# STM32H742AGI6 register map
File version: 1.0
Registers are 32-bit, access not given, reset 0x0 unless marked. A register's access mark holds for its fields unless they carry their own. Offsets are from the block's base; [hi:lo] are bit positions; {n}, {i} and the like mark numbered series; 'fields as' and 'values as' point back to an identical list.

## JPEG
Base 0x52003000
0x00 CONFR0
  [0] START
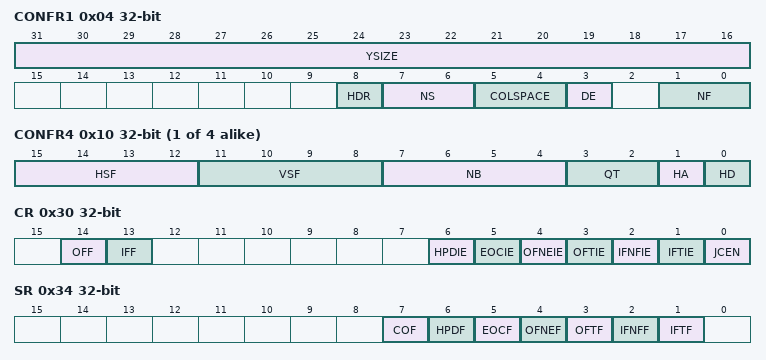
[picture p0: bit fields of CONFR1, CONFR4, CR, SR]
0x04 CONFR1
  [31:16] YSIZE, [8] HDR, [7:6] NS, [5:4] COLSPACE, [3] DE, [1:0] NF
0x08 CONFR2
  [25:0] NMCU
0x0C CONFR3
  [31:16] XSIZE
{0x0+4i} CONFR{i} (i=4..7)
  [15:12] HSF, [11:8] VSF, [7:4] NB, [3:2] QT, [1] HA, [0] HD
0x30 CR
  [14] OFF, [13] IFF, [6] HPDIE, [5] EOCIE, [4] OFNEIE, [3] OFTIE, [2] IFNFIE, [1] IFTIE, [0] JCEN
0x34 SR
  [7] COF, [6] HPDF, [5] EOCF, [4] OFNEF, [3] OFTF, [2] IFNFF, [1] IFTF
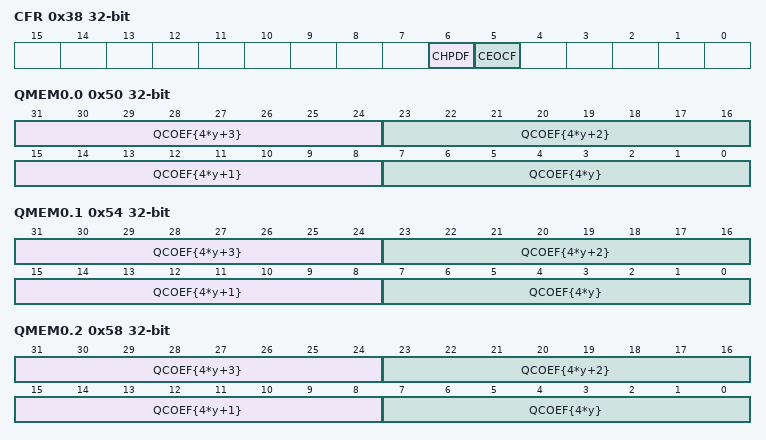
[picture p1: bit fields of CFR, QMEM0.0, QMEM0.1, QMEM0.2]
0x38 CFR
  [6] CHPDF, [5] CEOCF
0x40 DIR
  [31:0] DATAIN
0x44 DOR
  [31:0] DATAOUT
0x50 QMEM0.0
  [31:24] QCOEF{4*y+3}, [23:16] QCOEF{4*y+2}, [15:8] QCOEF{4*y+1}, [7:0] QCOEF{4*y}
0x54 QMEM0.1
  fields as QMEM0.0
0x58 QMEM0.2
  fields as QMEM0.0
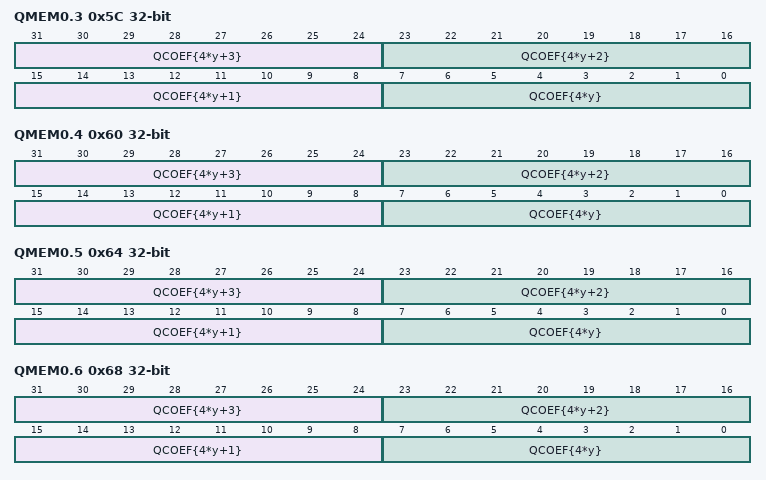
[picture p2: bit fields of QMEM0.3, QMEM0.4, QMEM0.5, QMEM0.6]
0x5C QMEM0.3
  fields as QMEM0.0
0x60 QMEM0.4
  fields as QMEM0.0
0x64 QMEM0.5
  fields as QMEM0.0
0x68 QMEM0.6
  fields as QMEM0.0
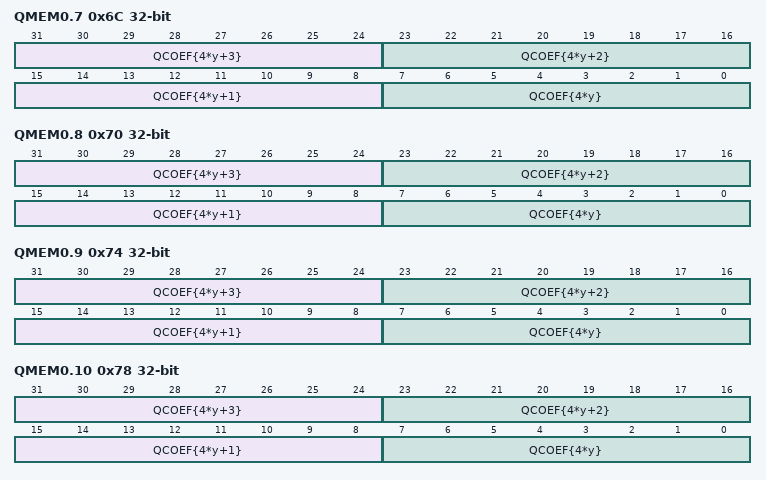
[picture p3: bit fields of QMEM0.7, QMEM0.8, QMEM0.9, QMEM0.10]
0x6C QMEM0.7
  fields as QMEM0.0
0x70 QMEM0.8
  fields as QMEM0.0
0x74 QMEM0.9
  fields as QMEM0.0
0x78 QMEM0.10
  fields as QMEM0.0
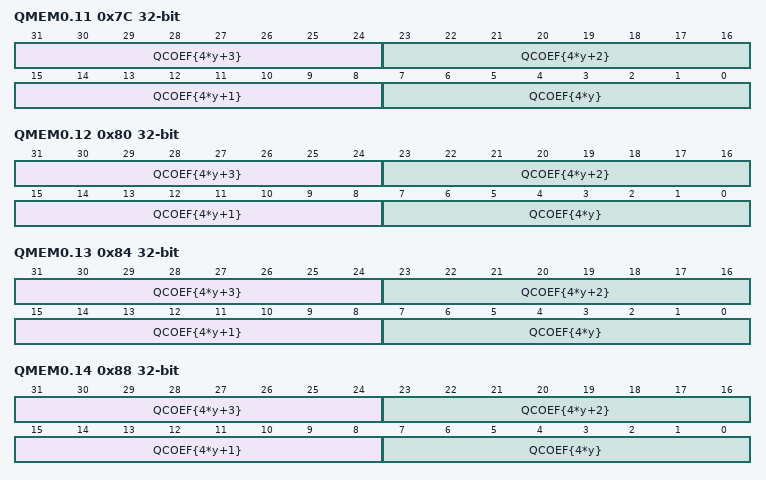
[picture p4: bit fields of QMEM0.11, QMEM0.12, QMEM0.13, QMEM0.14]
0x7C QMEM0.11
  fields as QMEM0.0
0x80 QMEM0.12
  fields as QMEM0.0
0x84 QMEM0.13
  fields as QMEM0.0
0x88 QMEM0.14
  fields as QMEM0.0
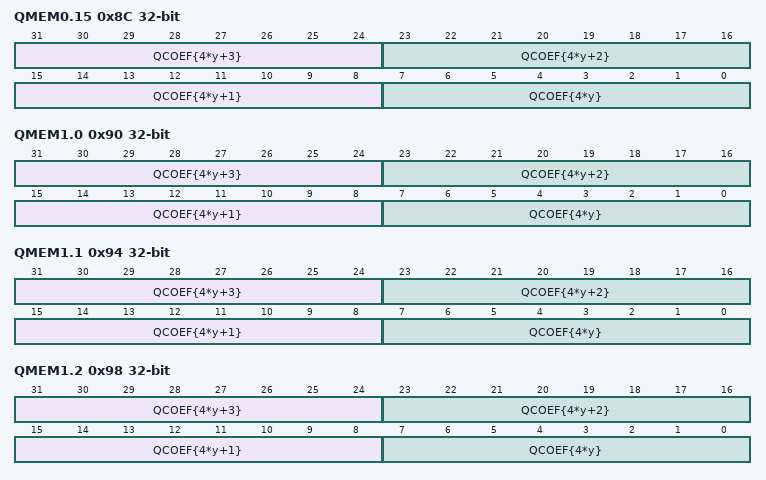
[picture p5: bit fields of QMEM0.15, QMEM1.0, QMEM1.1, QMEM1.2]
0x8C QMEM0.15
  fields as QMEM0.0
0x90 QMEM1.0
  fields as QMEM0.0
0x94 QMEM1.1
  fields as QMEM0.0
0x98 QMEM1.2
  fields as QMEM0.0
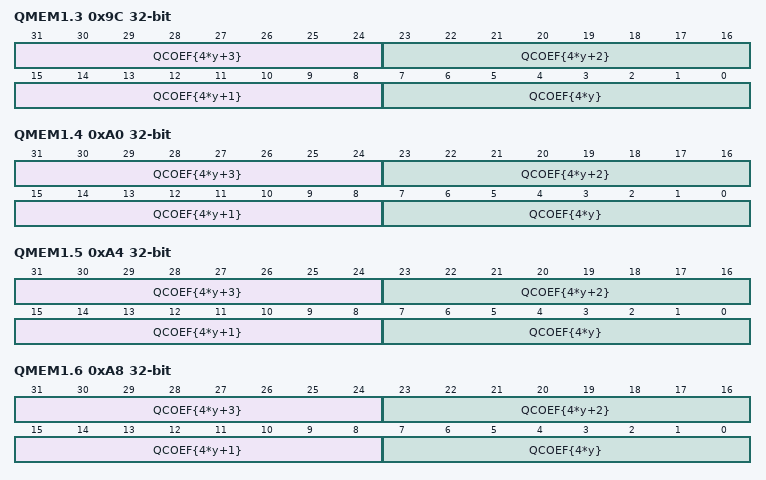
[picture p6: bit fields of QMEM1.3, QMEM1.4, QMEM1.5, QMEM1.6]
0x9C QMEM1.3
  fields as QMEM0.0
0xA0 QMEM1.4
  fields as QMEM0.0
0xA4 QMEM1.5
  fields as QMEM0.0
0xA8 QMEM1.6
  fields as QMEM0.0
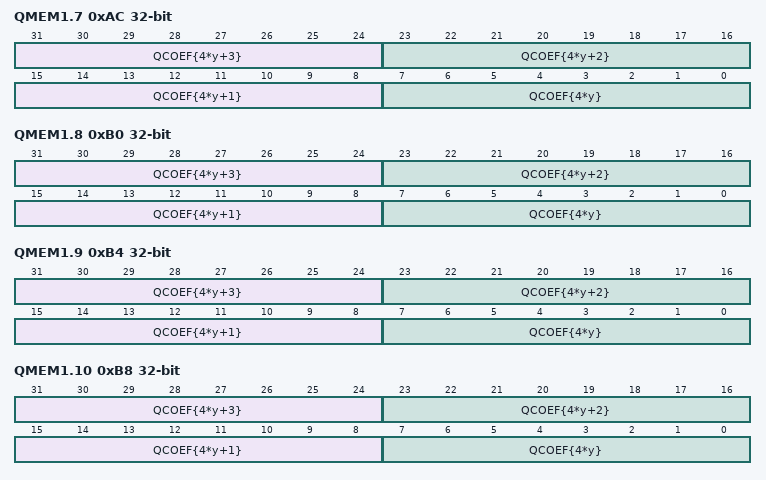
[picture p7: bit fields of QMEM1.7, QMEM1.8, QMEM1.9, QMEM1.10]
0xAC QMEM1.7
  fields as QMEM0.0
0xB0 QMEM1.8
  fields as QMEM0.0
0xB4 QMEM1.9
  fields as QMEM0.0
0xB8 QMEM1.10
  fields as QMEM0.0
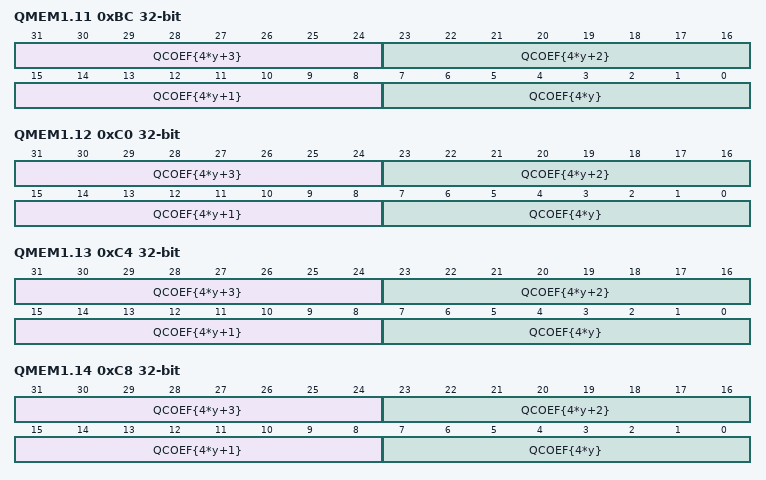
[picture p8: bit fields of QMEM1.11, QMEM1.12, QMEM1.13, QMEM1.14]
0xBC QMEM1.11
  fields as QMEM0.0
0xC0 QMEM1.12
  fields as QMEM0.0
0xC4 QMEM1.13
  fields as QMEM0.0
0xC8 QMEM1.14
  fields as QMEM0.0
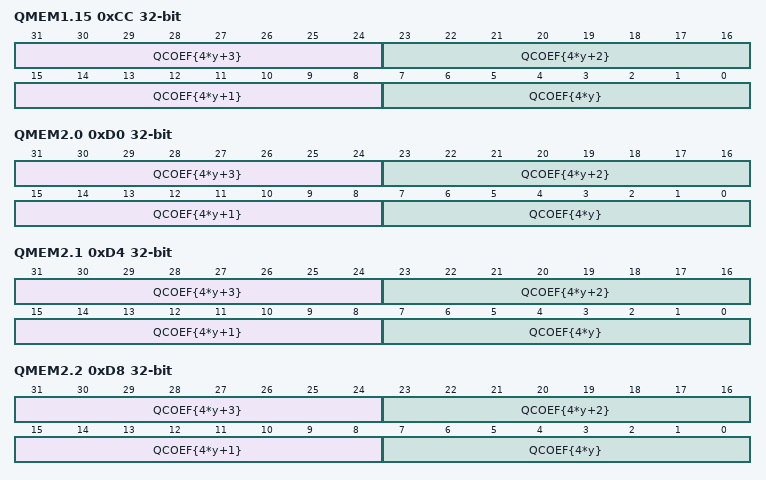
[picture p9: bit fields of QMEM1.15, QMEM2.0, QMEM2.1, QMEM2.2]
0xCC QMEM1.15
  fields as QMEM0.0
0xD0 QMEM2.0
  fields as QMEM0.0
0xD4 QMEM2.1
  fields as QMEM0.0
0xD8 QMEM2.2
  fields as QMEM0.0
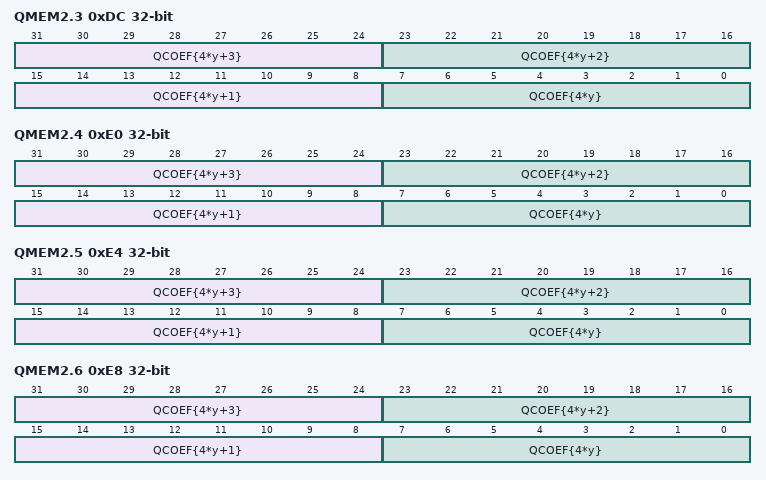
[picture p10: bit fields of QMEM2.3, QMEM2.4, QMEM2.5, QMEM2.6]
0xDC QMEM2.3
  fields as QMEM0.0
0xE0 QMEM2.4
  fields as QMEM0.0
0xE4 QMEM2.5
  fields as QMEM0.0
0xE8 QMEM2.6
  fields as QMEM0.0
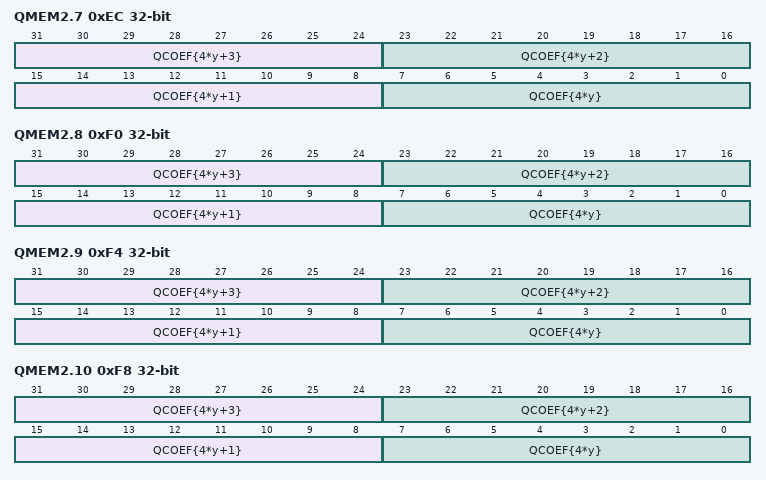
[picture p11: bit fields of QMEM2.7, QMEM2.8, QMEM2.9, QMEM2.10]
0xEC QMEM2.7
  fields as QMEM0.0
0xF0 QMEM2.8
  fields as QMEM0.0
0xF4 QMEM2.9
  fields as QMEM0.0
0xF8 QMEM2.10
  fields as QMEM0.0
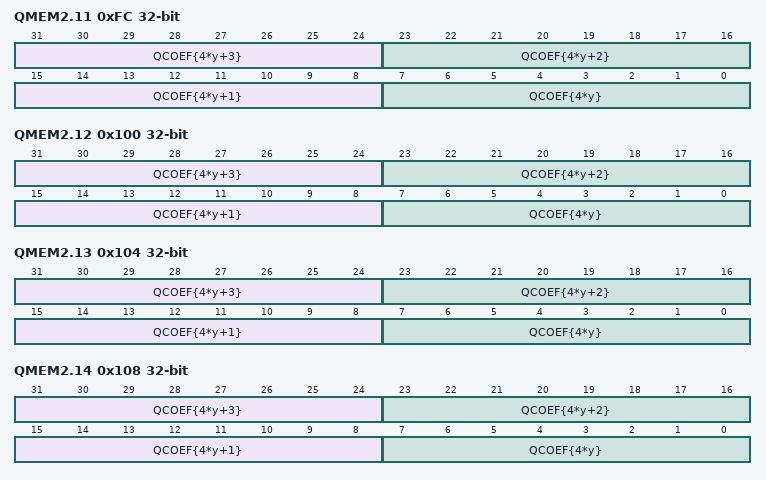
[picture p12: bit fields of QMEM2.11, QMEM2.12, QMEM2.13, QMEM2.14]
0xFC QMEM2.11
  fields as QMEM0.0
0x100 QMEM2.12
  fields as QMEM0.0
0x104 QMEM2.13
  fields as QMEM0.0
0x108 QMEM2.14
  fields as QMEM0.0
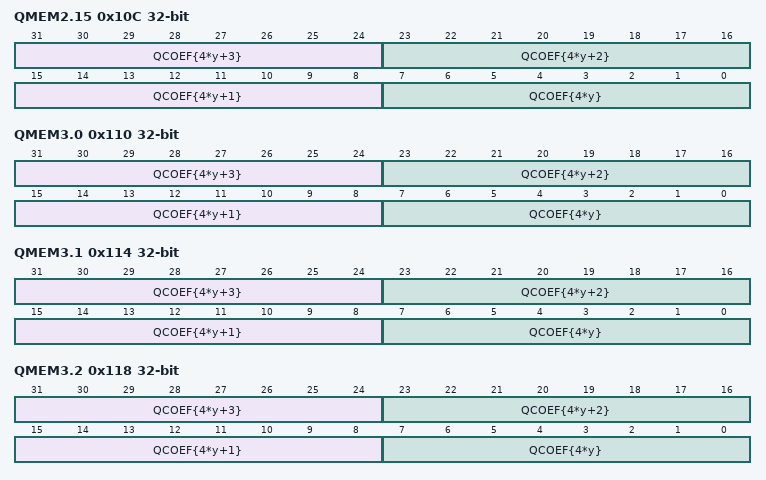
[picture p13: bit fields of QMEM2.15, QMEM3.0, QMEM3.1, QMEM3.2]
0x10C QMEM2.15
  fields as QMEM0.0
0x110 QMEM3.0
  fields as QMEM0.0
0x114 QMEM3.1
  fields as QMEM0.0
0x118 QMEM3.2
  fields as QMEM0.0
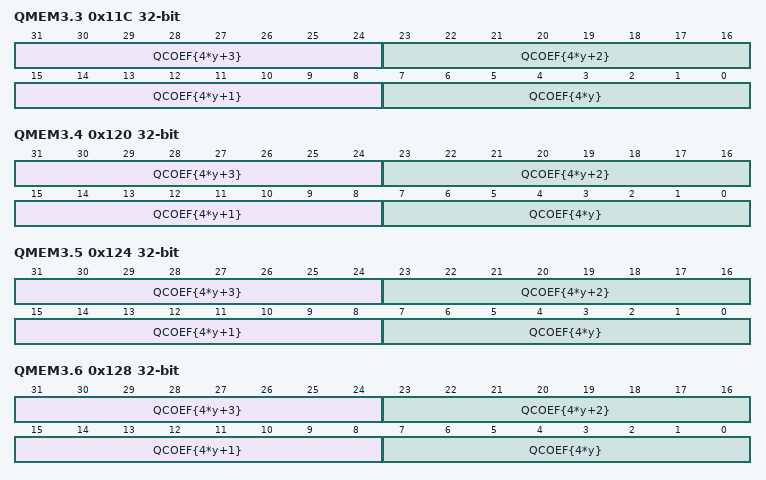
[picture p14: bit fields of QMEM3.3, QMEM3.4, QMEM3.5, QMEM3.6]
0x11C QMEM3.3
  fields as QMEM0.0
0x120 QMEM3.4
  fields as QMEM0.0
0x124 QMEM3.5
  fields as QMEM0.0
0x128 QMEM3.6
  fields as QMEM0.0
0x12C QMEM3.7
  fields as QMEM0.0
0x130 QMEM3.8
  fields as QMEM0.0
0x134 QMEM3.9
  fields as QMEM0.0
0x138 QMEM3.10
  fields as QMEM0.0
0x13C QMEM3.11
  fields as QMEM0.0
0x140 QMEM3.12
  fields as QMEM0.0
0x144 QMEM3.13
  fields as QMEM0.0
0x148 QMEM3.14
  fields as QMEM0.0
0x14C QMEM3.15
  fields as QMEM0.0
0x150 HUFFMIN.0
  [31:0] DATA{x}
0x154 HUFFMIN.1
  [31:0] DATA{x}
0x158 HUFFMIN.2
  [31:0] DATA{x}
0x15C HUFFMIN.3
  [31:0] DATA{x}
0x160 HUFFMIN.4
  [31:0] DATA{x}
0x164 HUFFMIN.5
  [31:0] DATA{x}
0x168 HUFFMIN.6
  [31:0] DATA{x}
0x16C HUFFMIN.7
  [31:0] DATA{x}
0x170 HUFFMIN.8
  [31:0] DATA{x}
0x174 HUFFMIN.9
  [31:0] DATA{x}
0x178 HUFFMIN.10
  [31:0] DATA{x}
0x17C HUFFMIN.11
  [31:0] DATA{x}
0x180 HUFFMIN.12
  [31:0] DATA{x}
0x184 HUFFMIN.13
  [31:0] DATA{x}
0x188 HUFFMIN.14
  [31:0] DATA{x}
0x18C HUFFMIN.15
  [31:0] DATA{x}
0x190 HUFFBASE.0
  [24:16] DATA{2*x+1}, [8:0] DATA{2*x}
0x194 HUFFBASE.1
  [24:16] DATA{2*x+1}, [8:0] DATA{2*x}
0x198 HUFFBASE.2
  [24:16] DATA{2*x+1}, [8:0] DATA{2*x}
0x19C HUFFBASE.3
  [24:16] DATA{2*x+1}, [8:0] DATA{2*x}
0x1A0 HUFFBASE.4
  [24:16] DATA{2*x+1}, [8:0] DATA{2*x}
0x1A4 HUFFBASE.5
  [24:16] DATA{2*x+1}, [8:0] DATA{2*x}
0x1A8 HUFFBASE.6
  [24:16] DATA{2*x+1}, [8:0] DATA{2*x}
0x1AC HUFFBASE.7
  [24:16] DATA{2*x+1}, [8:0] DATA{2*x}
0x1B0 HUFFBASE.8
  [24:16] DATA{2*x+1}, [8:0] DATA{2*x}
0x1B4 HUFFBASE.9
  [24:16] DATA{2*x+1}, [8:0] DATA{2*x}
0x1B8 HUFFBASE.10
  [24:16] DATA{2*x+1}, [8:0] DATA{2*x}
0x1BC HUFFBASE.11
  [24:16] DATA{2*x+1}, [8:0] DATA{2*x}
0x1C0 HUFFBASE.12
  [24:16] DATA{2*x+1}, [8:0] DATA{2*x}
0x1C4 HUFFBASE.13
  [24:16] DATA{2*x+1}, [8:0] DATA{2*x}
0x1C8 HUFFBASE.14
  [24:16] DATA{2*x+1}, [8:0] DATA{2*x}
0x1CC HUFFBASE.15
  [24:16] DATA{2*x+1}, [8:0] DATA{2*x}
0x1D0 HUFFBASE.16
  [24:16] DATA{2*x+1}, [8:0] DATA{2*x}
0x1D4 HUFFBASE.17
  [24:16] DATA{2*x+1}, [8:0] DATA{2*x}
0x1D8 HUFFBASE.18
  [24:16] DATA{2*x+1}, [8:0] DATA{2*x}
0x1DC HUFFBASE.19
  [24:16] DATA{2*x+1}, [8:0] DATA{2*x}
0x1E0 HUFFBASE.20
  [24:16] DATA{2*x+1}, [8:0] DATA{2*x}
0x1E4 HUFFBASE.21
  [24:16] DATA{2*x+1}, [8:0] DATA{2*x}
0x1E8 HUFFBASE.22
  [24:16] DATA{2*x+1}, [8:0] DATA{2*x}
0x1EC HUFFBASE.23
  [24:16] DATA{2*x+1}, [8:0] DATA{2*x}
0x1F0 HUFFBASE.24
  [24:16] DATA{2*x+1}, [8:0] DATA{2*x}
0x1F4 HUFFBASE.25
  [24:16] DATA{2*x+1}, [8:0] DATA{2*x}
0x1F8 HUFFBASE.26
  [24:16] DATA{2*x+1}, [8:0] DATA{2*x}
0x1FC HUFFBASE.27
  [24:16] DATA{2*x+1}, [8:0] DATA{2*x}
0x200 HUFFBASE.28
  [24:16] DATA{2*x+1}, [8:0] DATA{2*x}
0x204 HUFFBASE.29
  [24:16] DATA{2*x+1}, [8:0] DATA{2*x}
0x208 HUFFBASE.30
  [24:16] DATA{2*x+1}, [8:0] DATA{2*x}
0x20C HUFFBASE.31
  [24:16] DATA{2*x+1}, [8:0] DATA{2*x}
0x210 HUFFSYMB.0
  [31:24] DATA{4*x+3}, [23:16] DATA{4*x+2}, [15:8] DATA{4*x+1}, [7:0] DATA{4*x}
0x214 HUFFSYMB.1
  fields as HUFFSYMB.0
0x218 HUFFSYMB.2
  fields as HUFFSYMB.0
0x21C HUFFSYMB.3
  fields as HUFFSYMB.0
0x220 HUFFSYMB.4
  fields as HUFFSYMB.0
0x224 HUFFSYMB.5
  fields as HUFFSYMB.0
0x228 HUFFSYMB.6
  fields as HUFFSYMB.0
0x22C HUFFSYMB.7
  fields as HUFFSYMB.0
0x230 HUFFSYMB.8
  fields as HUFFSYMB.0
0x234 HUFFSYMB.9
  fields as HUFFSYMB.0
0x238 HUFFSYMB.10
  fields as HUFFSYMB.0
0x23C HUFFSYMB.11
  fields as HUFFSYMB.0
0x240 HUFFSYMB.12
  fields as HUFFSYMB.0
0x244 HUFFSYMB.13
  fields as HUFFSYMB.0
0x248 HUFFSYMB.14
  fields as HUFFSYMB.0
0x24C HUFFSYMB.15
  fields as HUFFSYMB.0
0x250 HUFFSYMB.16
  fields as HUFFSYMB.0
0x254 HUFFSYMB.17
  fields as HUFFSYMB.0
0x258 HUFFSYMB.18
  fields as HUFFSYMB.0
0x25C HUFFSYMB.19
  fields as HUFFSYMB.0
0x260 HUFFSYMB.20
  fields as HUFFSYMB.0
0x264 HUFFSYMB.21
  fields as HUFFSYMB.0
0x268 HUFFSYMB.22
  fields as HUFFSYMB.0
0x26C HUFFSYMB.23
  fields as HUFFSYMB.0
0x270 HUFFSYMB.24
  fields as HUFFSYMB.0
0x274 HUFFSYMB.25
  fields as HUFFSYMB.0
0x278 HUFFSYMB.26
  fields as HUFFSYMB.0
0x27C HUFFSYMB.27
  fields as HUFFSYMB.0
0x280 HUFFSYMB.28
  fields as HUFFSYMB.0
0x284 HUFFSYMB.29
  fields as HUFFSYMB.0
0x288 HUFFSYMB.30
  fields as HUFFSYMB.0
0x28C HUFFSYMB.31
  fields as HUFFSYMB.0
0x290 HUFFSYMB.32
  fields as HUFFSYMB.0
0x294 HUFFSYMB.33
  fields as HUFFSYMB.0
0x298 HUFFSYMB.34
  fields as HUFFSYMB.0
0x29C HUFFSYMB.35
  fields as HUFFSYMB.0
0x2A0 HUFFSYMB.36
  fields as HUFFSYMB.0
0x2A4 HUFFSYMB.37
  fields as HUFFSYMB.0
0x2A8 HUFFSYMB.38
  fields as HUFFSYMB.0
0x2AC HUFFSYMB.39
  fields as HUFFSYMB.0
0x2B0 HUFFSYMB.40
  fields as HUFFSYMB.0
0x2B4 HUFFSYMB.41
  fields as HUFFSYMB.0
0x2B8 HUFFSYMB.42
  fields as HUFFSYMB.0
0x2BC HUFFSYMB.43
  fields as HUFFSYMB.0
0x2C0 HUFFSYMB.44
  fields as HUFFSYMB.0
0x2C4 HUFFSYMB.45
  fields as HUFFSYMB.0
0x2C8 HUFFSYMB.46
  fields as HUFFSYMB.0
0x2CC HUFFSYMB.47
  fields as HUFFSYMB.0
0x2D0 HUFFSYMB.48
  fields as HUFFSYMB.0
0x2D4 HUFFSYMB.49
  fields as HUFFSYMB.0
0x2D8 HUFFSYMB.50
  fields as HUFFSYMB.0
0x2DC HUFFSYMB.51
  fields as HUFFSYMB.0
0x2E0 HUFFSYMB.52
  fields as HUFFSYMB.0
0x2E4 HUFFSYMB.53
  fields as HUFFSYMB.0
0x2E8 HUFFSYMB.54
  fields as HUFFSYMB.0
0x2EC HUFFSYMB.55
  fields as HUFFSYMB.0
0x2F0 HUFFSYMB.56
  fields as HUFFSYMB.0
0x2F4 HUFFSYMB.57
  fields as HUFFSYMB.0
0x2F8 HUFFSYMB.58
  fields as HUFFSYMB.0
0x2FC HUFFSYMB.59
  fields as HUFFSYMB.0
0x300 HUFFSYMB.60
  fields as HUFFSYMB.0
0x304 HUFFSYMB.61
  fields as HUFFSYMB.0
0x308 HUFFSYMB.62
  fields as HUFFSYMB.0
0x30C HUFFSYMB.63
  fields as HUFFSYMB.0
0x310 HUFFSYMB.64
  fields as HUFFSYMB.0
0x314 HUFFSYMB.65
  fields as HUFFSYMB.0
0x318 HUFFSYMB.66
  fields as HUFFSYMB.0
0x31C HUFFSYMB.67
  fields as HUFFSYMB.0
0x320 HUFFSYMB.68
  fields as HUFFSYMB.0
0x324 HUFFSYMB.69
  fields as HUFFSYMB.0
0x328 HUFFSYMB.70
  fields as HUFFSYMB.0
0x32C HUFFSYMB.71
  fields as HUFFSYMB.0
0x330 HUFFSYMB.72
  fields as HUFFSYMB.0
0x334 HUFFSYMB.73
  fields as HUFFSYMB.0
0x338 HUFFSYMB.74
  fields as HUFFSYMB.0
0x33C HUFFSYMB.75
  fields as HUFFSYMB.0
0x340 HUFFSYMB.76
  fields as HUFFSYMB.0
0x344 HUFFSYMB.77
  fields as HUFFSYMB.0
0x348 HUFFSYMB.78
  fields as HUFFSYMB.0
0x34C HUFFSYMB.79
  fields as HUFFSYMB.0
0x350 HUFFSYMB.80
  fields as HUFFSYMB.0
0x354 HUFFSYMB.81
  fields as HUFFSYMB.0
0x358 HUFFSYMB.82
  fields as HUFFSYMB.0
0x35C HUFFSYMB.83
  fields as HUFFSYMB.0
0x360 DHTMEM.0
  fields as HUFFSYMB.0
0x364 DHTMEM.1
  fields as HUFFSYMB.0
0x368 DHTMEM.2
  fields as HUFFSYMB.0
0x36C DHTMEM.3
  fields as HUFFSYMB.0
0x370 DHTMEM.4
  fields as HUFFSYMB.0
0x374 DHTMEM.5
  fields as HUFFSYMB.0
0x378 DHTMEM.6
  fields as HUFFSYMB.0
0x37C DHTMEM.7
  fields as HUFFSYMB.0
0x380 DHTMEM.8
  fields as HUFFSYMB.0
0x384 DHTMEM.9
  fields as HUFFSYMB.0
0x388 DHTMEM.10
  fields as HUFFSYMB.0
0x38C DHTMEM.11
  fields as HUFFSYMB.0
0x390 DHTMEM.12
  fields as HUFFSYMB.0
0x394 DHTMEM.13
  fields as HUFFSYMB.0
0x398 DHTMEM.14
  fields as HUFFSYMB.0
0x39C DHTMEM.15
  fields as HUFFSYMB.0
0x3A0 DHTMEM.16
  fields as HUFFSYMB.0
0x3A4 DHTMEM.17
  fields as HUFFSYMB.0
0x3A8 DHTMEM.18
  fields as HUFFSYMB.0
0x3AC DHTMEM.19
  fields as HUFFSYMB.0
0x3B0 DHTMEM.20
  fields as HUFFSYMB.0
0x3B4 DHTMEM.21
  fields as HUFFSYMB.0
0x3B8 DHTMEM.22
  fields as HUFFSYMB.0
0x3BC DHTMEM.23
  fields as HUFFSYMB.0
0x3C0 DHTMEM.24
  fields as HUFFSYMB.0
0x3C4 DHTMEM.25
  fields as HUFFSYMB.0
0x3C8 DHTMEM.26
  fields as HUFFSYMB.0
0x3CC DHTMEM.27
  fields as HUFFSYMB.0
0x3D0 DHTMEM.28
  fields as HUFFSYMB.0
0x3D4 DHTMEM.29
  fields as HUFFSYMB.0
0x3D8 DHTMEM.30
  fields as HUFFSYMB.0
0x3DC DHTMEM.31
  fields as HUFFSYMB.0
0x3E0 DHTMEM.32
  fields as HUFFSYMB.0
0x3E4 DHTMEM.33
  fields as HUFFSYMB.0
0x3E8 DHTMEM.34
  fields as HUFFSYMB.0
0x3EC DHTMEM.35
  fields as HUFFSYMB.0
0x3F0 DHTMEM.36
  fields as HUFFSYMB.0
0x3F4 DHTMEM.37
  fields as HUFFSYMB.0
0x3F8 DHTMEM.38
  fields as HUFFSYMB.0
0x3FC DHTMEM.39
  fields as HUFFSYMB.0
0x400 DHTMEM.40
  fields as HUFFSYMB.0
0x404 DHTMEM.41
  fields as HUFFSYMB.0
0x408 DHTMEM.42
  fields as HUFFSYMB.0
0x40C DHTMEM.43
  fields as HUFFSYMB.0
0x410 DHTMEM.44
  fields as HUFFSYMB.0
0x414 DHTMEM.45
  fields as HUFFSYMB.0
0x418 DHTMEM.46
  fields as HUFFSYMB.0
0x41C DHTMEM.47
  fields as HUFFSYMB.0
0x420 DHTMEM.48
  fields as HUFFSYMB.0
0x424 DHTMEM.49
  fields as HUFFSYMB.0
0x428 DHTMEM.50
  fields as HUFFSYMB.0
0x42C DHTMEM.51
  fields as HUFFSYMB.0
0x430 DHTMEM.52
  fields as HUFFSYMB.0
0x434 DHTMEM.53
  fields as HUFFSYMB.0
0x438 DHTMEM.54
  fields as HUFFSYMB.0
0x43C DHTMEM.55
  fields as HUFFSYMB.0
0x440 DHTMEM.56
  fields as HUFFSYMB.0
0x444 DHTMEM.57
  fields as HUFFSYMB.0
0x448 DHTMEM.58
  fields as HUFFSYMB.0
0x44C DHTMEM.59
  fields as HUFFSYMB.0
0x450 DHTMEM.60
  fields as HUFFSYMB.0
0x454 DHTMEM.61
  fields as HUFFSYMB.0
0x458 DHTMEM.62
  fields as HUFFSYMB.0
0x45C DHTMEM.63
  fields as HUFFSYMB.0
0x460 DHTMEM.64
  fields as HUFFSYMB.0
0x464 DHTMEM.65
  fields as HUFFSYMB.0
0x468 DHTMEM.66
  fields as HUFFSYMB.0
0x46C DHTMEM.67
  fields as HUFFSYMB.0
0x470 DHTMEM.68
  fields as HUFFSYMB.0
0x474 DHTMEM.69
  fields as HUFFSYMB.0
0x478 DHTMEM.70
  fields as HUFFSYMB.0
0x47C DHTMEM.71
  fields as HUFFSYMB.0
0x480 DHTMEM.72
  fields as HUFFSYMB.0
0x484 DHTMEM.73
  fields as HUFFSYMB.0
0x488 DHTMEM.74
  fields as HUFFSYMB.0
0x48C DHTMEM.75
  fields as HUFFSYMB.0
0x490 DHTMEM.76
  fields as HUFFSYMB.0
0x494 DHTMEM.77
  fields as HUFFSYMB.0
0x498 DHTMEM.78
  fields as HUFFSYMB.0
0x49C DHTMEM.79
  fields as HUFFSYMB.0
0x4A0 DHTMEM.80
  fields as HUFFSYMB.0
0x4A4 DHTMEM.81
  fields as HUFFSYMB.0
0x4A8 DHTMEM.82
  fields as HUFFSYMB.0
0x4AC DHTMEM.83
  fields as HUFFSYMB.0
0x4B0 DHTMEM.84
  fields as HUFFSYMB.0
0x4B4 DHTMEM.85
  fields as HUFFSYMB.0
0x4B8 DHTMEM.86
  fields as HUFFSYMB.0
0x4BC DHTMEM.87
  fields as HUFFSYMB.0
0x4C0 DHTMEM.88
  fields as HUFFSYMB.0
0x4C4 DHTMEM.89
  fields as HUFFSYMB.0
0x4C8 DHTMEM.90
  fields as HUFFSYMB.0
0x4CC DHTMEM.91
  fields as HUFFSYMB.0
0x4D0 DHTMEM.92
  fields as HUFFSYMB.0
0x4D4 DHTMEM.93
  fields as HUFFSYMB.0
0x4D8 DHTMEM.94
  fields as HUFFSYMB.0
0x4DC DHTMEM.95
  fields as HUFFSYMB.0
0x4E0 DHTMEM.96
  fields as HUFFSYMB.0
0x4E4 DHTMEM.97
  fields as HUFFSYMB.0
0x4E8 DHTMEM.98
  fields as HUFFSYMB.0
0x4EC DHTMEM.99
  fields as HUFFSYMB.0
0x4F0 DHTMEM.100
  fields as HUFFSYMB.0
0x4F4 DHTMEM.101
  fields as HUFFSYMB.0
0x4F8 DHTMEM.102
  fields as HUFFSYMB.0
0x500 HUFFENC_AC0.0
  [27:24] HLEN{2*y+1}, [23:16] HCODE{2*y+1}, [11:8] HLEN{2*y}, [7:0] HCODE{2*y}
0x504 HUFFENC_AC0.1
  fields as HUFFENC_AC0.0
0x508 HUFFENC_AC0.2
  fields as HUFFENC_AC0.0
0x50C HUFFENC_AC0.3
  fields as HUFFENC_AC0.0
0x510 HUFFENC_AC0.4
  fields as HUFFENC_AC0.0
0x514 HUFFENC_AC0.5
  fields as HUFFENC_AC0.0
0x518 HUFFENC_AC0.6
  fields as HUFFENC_AC0.0
0x51C HUFFENC_AC0.7
  fields as HUFFENC_AC0.0
0x520 HUFFENC_AC0.8
  fields as HUFFENC_AC0.0
0x524 HUFFENC_AC0.9
  fields as HUFFENC_AC0.0
0x528 HUFFENC_AC0.10
  fields as HUFFENC_AC0.0
0x52C HUFFENC_AC0.11
  fields as HUFFENC_AC0.0
0x530 HUFFENC_AC0.12
  fields as HUFFENC_AC0.0
0x534 HUFFENC_AC0.13
  fields as HUFFENC_AC0.0
0x538 HUFFENC_AC0.14
  fields as HUFFENC_AC0.0
0x53C HUFFENC_AC0.15
  fields as HUFFENC_AC0.0
0x540 HUFFENC_AC0.16
  fields as HUFFENC_AC0.0
0x544 HUFFENC_AC0.17
  fields as HUFFENC_AC0.0
0x548 HUFFENC_AC0.18
  fields as HUFFENC_AC0.0
0x54C HUFFENC_AC0.19
  fields as HUFFENC_AC0.0
0x550 HUFFENC_AC0.20
  fields as HUFFENC_AC0.0
0x554 HUFFENC_AC0.21
  fields as HUFFENC_AC0.0
0x558 HUFFENC_AC0.22
  fields as HUFFENC_AC0.0
0x55C HUFFENC_AC0.23
  fields as HUFFENC_AC0.0
0x560 HUFFENC_AC0.24
  fields as HUFFENC_AC0.0
0x564 HUFFENC_AC0.25
  fields as HUFFENC_AC0.0
0x568 HUFFENC_AC0.26
  fields as HUFFENC_AC0.0
0x56C HUFFENC_AC0.27
  fields as HUFFENC_AC0.0
0x570 HUFFENC_AC0.28
  fields as HUFFENC_AC0.0
0x574 HUFFENC_AC0.29
  fields as HUFFENC_AC0.0
0x578 HUFFENC_AC0.30
  fields as HUFFENC_AC0.0
0x57C HUFFENC_AC0.31
  fields as HUFFENC_AC0.0
0x580 HUFFENC_AC0.32
  fields as HUFFENC_AC0.0
0x584 HUFFENC_AC0.33
  fields as HUFFENC_AC0.0
0x588 HUFFENC_AC0.34
  fields as HUFFENC_AC0.0
0x58C HUFFENC_AC0.35
  fields as HUFFENC_AC0.0
0x590 HUFFENC_AC0.36
  fields as HUFFENC_AC0.0
0x594 HUFFENC_AC0.37
  fields as HUFFENC_AC0.0
0x598 HUFFENC_AC0.38
  fields as HUFFENC_AC0.0
0x59C HUFFENC_AC0.39
  fields as HUFFENC_AC0.0
0x5A0 HUFFENC_AC0.40
  fields as HUFFENC_AC0.0
0x5A4 HUFFENC_AC0.41
  fields as HUFFENC_AC0.0
0x5A8 HUFFENC_AC0.42
  fields as HUFFENC_AC0.0
0x5AC HUFFENC_AC0.43
  fields as HUFFENC_AC0.0
0x5B0 HUFFENC_AC0.44
  fields as HUFFENC_AC0.0
0x5B4 HUFFENC_AC0.45
  fields as HUFFENC_AC0.0
0x5B8 HUFFENC_AC0.46
  fields as HUFFENC_AC0.0
0x5BC HUFFENC_AC0.47
  fields as HUFFENC_AC0.0
0x5C0 HUFFENC_AC0.48
  fields as HUFFENC_AC0.0
0x5C4 HUFFENC_AC0.49
  fields as HUFFENC_AC0.0
0x5C8 HUFFENC_AC0.50
  fields as HUFFENC_AC0.0
0x5CC HUFFENC_AC0.51
  fields as HUFFENC_AC0.0
0x5D0 HUFFENC_AC0.52
  fields as HUFFENC_AC0.0
0x5D4 HUFFENC_AC0.53
  fields as HUFFENC_AC0.0
0x5D8 HUFFENC_AC0.54
  fields as HUFFENC_AC0.0
0x5DC HUFFENC_AC0.55
  fields as HUFFENC_AC0.0
0x5E0 HUFFENC_AC0.56
  fields as HUFFENC_AC0.0
0x5E4 HUFFENC_AC0.57
  fields as HUFFENC_AC0.0
0x5E8 HUFFENC_AC0.58
  fields as HUFFENC_AC0.0
0x5EC HUFFENC_AC0.59
  fields as HUFFENC_AC0.0
0x5F0 HUFFENC_AC0.60
  fields as HUFFENC_AC0.0
0x5F4 HUFFENC_AC0.61
  fields as HUFFENC_AC0.0
0x5F8 HUFFENC_AC0.62
  fields as HUFFENC_AC0.0
0x5FC HUFFENC_AC0.63
  fields as HUFFENC_AC0.0
0x600 HUFFENC_AC0.64
  fields as HUFFENC_AC0.0
0x604 HUFFENC_AC0.65
  fields as HUFFENC_AC0.0
0x608 HUFFENC_AC0.66
  fields as HUFFENC_AC0.0
0x60C HUFFENC_AC0.67
  fields as HUFFENC_AC0.0
0x610 HUFFENC_AC0.68
  fields as HUFFENC_AC0.0
0x614 HUFFENC_AC0.69
  fields as HUFFENC_AC0.0
0x618 HUFFENC_AC0.70
  fields as HUFFENC_AC0.0
0x61C HUFFENC_AC0.71
  fields as HUFFENC_AC0.0
0x620 HUFFENC_AC0.72
  fields as HUFFENC_AC0.0
0x624 HUFFENC_AC0.73
  fields as HUFFENC_AC0.0
0x628 HUFFENC_AC0.74
  fields as HUFFENC_AC0.0
0x62C HUFFENC_AC0.75
  fields as HUFFENC_AC0.0
0x630 HUFFENC_AC0.76
  fields as HUFFENC_AC0.0
0x634 HUFFENC_AC0.77
  fields as HUFFENC_AC0.0
0x638 HUFFENC_AC0.78
  fields as HUFFENC_AC0.0
0x63C HUFFENC_AC0.79
  fields as HUFFENC_AC0.0
0x640 HUFFENC_AC0.80
  fields as HUFFENC_AC0.0
0x644 HUFFENC_AC0.81
  fields as HUFFENC_AC0.0
0x648 HUFFENC_AC0.82
  fields as HUFFENC_AC0.0
0x64C HUFFENC_AC0.83
  fields as HUFFENC_AC0.0
0x650 HUFFENC_AC0.84
  fields as HUFFENC_AC0.0
0x654 HUFFENC_AC0.85
  fields as HUFFENC_AC0.0
0x658 HUFFENC_AC0.86
  fields as HUFFENC_AC0.0
0x65C HUFFENC_AC0.87
  fields as HUFFENC_AC0.0
0x660 HUFFENC_AC1.0
  fields as HUFFENC_AC0.0
0x664 HUFFENC_AC1.1
  fields as HUFFENC_AC0.0
0x668 HUFFENC_AC1.2
  fields as HUFFENC_AC0.0
0x66C HUFFENC_AC1.3
  fields as HUFFENC_AC0.0
0x670 HUFFENC_AC1.4
  fields as HUFFENC_AC0.0
0x674 HUFFENC_AC1.5
  fields as HUFFENC_AC0.0
0x678 HUFFENC_AC1.6
  fields as HUFFENC_AC0.0
0x67C HUFFENC_AC1.7
  fields as HUFFENC_AC0.0
0x680 HUFFENC_AC1.8
  fields as HUFFENC_AC0.0
0x684 HUFFENC_AC1.9
  fields as HUFFENC_AC0.0
0x688 HUFFENC_AC1.10
  fields as HUFFENC_AC0.0
0x68C HUFFENC_AC1.11
  fields as HUFFENC_AC0.0
0x690 HUFFENC_AC1.12
  fields as HUFFENC_AC0.0
0x694 HUFFENC_AC1.13
  fields as HUFFENC_AC0.0
0x698 HUFFENC_AC1.14
  fields as HUFFENC_AC0.0
0x69C HUFFENC_AC1.15
  fields as HUFFENC_AC0.0
0x6A0 HUFFENC_AC1.16
  fields as HUFFENC_AC0.0
0x6A4 HUFFENC_AC1.17
  fields as HUFFENC_AC0.0
0x6A8 HUFFENC_AC1.18
  fields as HUFFENC_AC0.0
0x6AC HUFFENC_AC1.19
  fields as HUFFENC_AC0.0
0x6B0 HUFFENC_AC1.20
  fields as HUFFENC_AC0.0
0x6B4 HUFFENC_AC1.21
  fields as HUFFENC_AC0.0
0x6B8 HUFFENC_AC1.22
  fields as HUFFENC_AC0.0
0x6BC HUFFENC_AC1.23
  fields as HUFFENC_AC0.0
0x6C0 HUFFENC_AC1.24
  fields as HUFFENC_AC0.0
0x6C4 HUFFENC_AC1.25
  fields as HUFFENC_AC0.0
0x6C8 HUFFENC_AC1.26
  fields as HUFFENC_AC0.0
0x6CC HUFFENC_AC1.27
  fields as HUFFENC_AC0.0
0x6D0 HUFFENC_AC1.28
  fields as HUFFENC_AC0.0
0x6D4 HUFFENC_AC1.29
  fields as HUFFENC_AC0.0
0x6D8 HUFFENC_AC1.30
  fields as HUFFENC_AC0.0
0x6DC HUFFENC_AC1.31
  fields as HUFFENC_AC0.0
0x6E0 HUFFENC_AC1.32
  fields as HUFFENC_AC0.0
0x6E4 HUFFENC_AC1.33
  fields as HUFFENC_AC0.0
0x6E8 HUFFENC_AC1.34
  fields as HUFFENC_AC0.0
0x6EC HUFFENC_AC1.35
  fields as HUFFENC_AC0.0
0x6F0 HUFFENC_AC1.36
  fields as HUFFENC_AC0.0
0x6F4 HUFFENC_AC1.37
  fields as HUFFENC_AC0.0
0x6F8 HUFFENC_AC1.38
  fields as HUFFENC_AC0.0
0x6FC HUFFENC_AC1.39
  fields as HUFFENC_AC0.0
0x700 HUFFENC_AC1.40
  fields as HUFFENC_AC0.0
0x704 HUFFENC_AC1.41
  fields as HUFFENC_AC0.0
0x708 HUFFENC_AC1.42
  fields as HUFFENC_AC0.0
0x70C HUFFENC_AC1.43
  fields as HUFFENC_AC0.0
0x710 HUFFENC_AC1.44
  fields as HUFFENC_AC0.0
0x714 HUFFENC_AC1.45
  fields as HUFFENC_AC0.0
0x718 HUFFENC_AC1.46
  fields as HUFFENC_AC0.0
0x71C HUFFENC_AC1.47
  fields as HUFFENC_AC0.0
0x720 HUFFENC_AC1.48
  fields as HUFFENC_AC0.0
0x724 HUFFENC_AC1.49
  fields as HUFFENC_AC0.0
0x728 HUFFENC_AC1.50
  fields as HUFFENC_AC0.0
0x72C HUFFENC_AC1.51
  fields as HUFFENC_AC0.0
0x730 HUFFENC_AC1.52
  fields as HUFFENC_AC0.0
0x734 HUFFENC_AC1.53
  fields as HUFFENC_AC0.0
0x738 HUFFENC_AC1.54
  fields as HUFFENC_AC0.0
0x73C HUFFENC_AC1.55
  fields as HUFFENC_AC0.0
0x740 HUFFENC_AC1.56
  fields as HUFFENC_AC0.0
0x744 HUFFENC_AC1.57
  fields as HUFFENC_AC0.0
0x748 HUFFENC_AC1.58
  fields as HUFFENC_AC0.0
0x74C HUFFENC_AC1.59
  fields as HUFFENC_AC0.0
0x750 HUFFENC_AC1.60
  fields as HUFFENC_AC0.0
0x754 HUFFENC_AC1.61
  fields as HUFFENC_AC0.0
0x758 HUFFENC_AC1.62
  fields as HUFFENC_AC0.0
0x75C HUFFENC_AC1.63
  fields as HUFFENC_AC0.0
0x760 HUFFENC_AC1.64
  fields as HUFFENC_AC0.0
0x764 HUFFENC_AC1.65
  fields as HUFFENC_AC0.0
0x768 HUFFENC_AC1.66
  fields as HUFFENC_AC0.0
0x76C HUFFENC_AC1.67
  fields as HUFFENC_AC0.0
0x770 HUFFENC_AC1.68
  fields as HUFFENC_AC0.0
0x774 HUFFENC_AC1.69
  fields as HUFFENC_AC0.0
0x778 HUFFENC_AC1.70
  fields as HUFFENC_AC0.0
0x77C HUFFENC_AC1.71
  fields as HUFFENC_AC0.0
0x780 HUFFENC_AC1.72
  fields as HUFFENC_AC0.0
0x784 HUFFENC_AC1.73
  fields as HUFFENC_AC0.0
0x788 HUFFENC_AC1.74
  fields as HUFFENC_AC0.0
0x78C HUFFENC_AC1.75
  fields as HUFFENC_AC0.0
0x790 HUFFENC_AC1.76
  fields as HUFFENC_AC0.0
0x794 HUFFENC_AC1.77
  fields as HUFFENC_AC0.0
0x798 HUFFENC_AC1.78
  fields as HUFFENC_AC0.0
0x79C HUFFENC_AC1.79
  fields as HUFFENC_AC0.0
0x7A0 HUFFENC_AC1.80
  fields as HUFFENC_AC0.0
0x7A4 HUFFENC_AC1.81
  fields as HUFFENC_AC0.0
0x7A8 HUFFENC_AC1.82
  fields as HUFFENC_AC0.0
0x7AC HUFFENC_AC1.83
  fields as HUFFENC_AC0.0
0x7B0 HUFFENC_AC1.84
  fields as HUFFENC_AC0.0
0x7B4 HUFFENC_AC1.85
  fields as HUFFENC_AC0.0
0x7B8 HUFFENC_AC1.86
  fields as HUFFENC_AC0.0
0x7BC HUFFENC_AC1.87
  fields as HUFFENC_AC0.0
0x7C0 HUFFENC_DC0.0
  fields as HUFFENC_AC0.0
0x7C4 HUFFENC_DC0.1
  fields as HUFFENC_AC0.0
0x7C8 HUFFENC_DC0.2
  fields as HUFFENC_AC0.0
0x7CC HUFFENC_DC0.3
  fields as HUFFENC_AC0.0
0x7D0 HUFFENC_DC0.4
  fields as HUFFENC_AC0.0
0x7D4 HUFFENC_DC0.5
  fields as HUFFENC_AC0.0
0x7D8 HUFFENC_DC0.6
  fields as HUFFENC_AC0.0
0x7DC HUFFENC_DC0.7
  fields as HUFFENC_AC0.0
0x7E0 HUFFENC_DC1.0
  fields as HUFFENC_AC0.0
0x7E4 HUFFENC_DC1.1
  fields as HUFFENC_AC0.0
0x7E8 HUFFENC_DC1.2
  fields as HUFFENC_AC0.0
0x7EC HUFFENC_DC1.3
  fields as HUFFENC_AC0.0
0x7F0 HUFFENC_DC1.4
  fields as HUFFENC_AC0.0
0x7F4 HUFFENC_DC1.5
  fields as HUFFENC_AC0.0
0x7F8 HUFFENC_DC1.6
  fields as HUFFENC_AC0.0
0x7FC HUFFENC_DC1.7
  fields as HUFFENC_AC0.0
